VERSION ""

NS_ :

BS_:

BU_: NOONE SENSOR DRIVER MOTOR IO

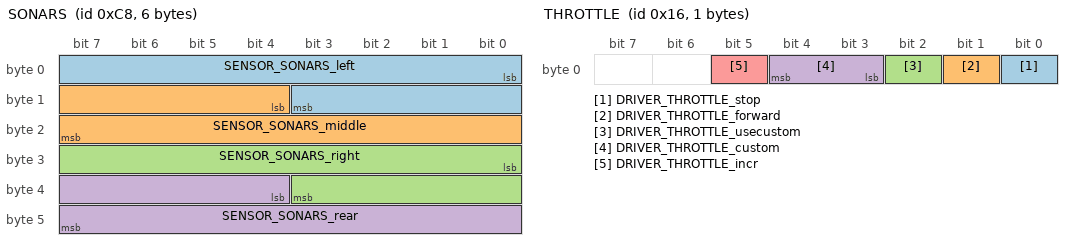
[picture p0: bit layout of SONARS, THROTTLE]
BO_ 200 SONARS: 6 SENSOR
 SG_ SENSOR_SONARS_left : 0|12@1+ (0.1,0) [0|0] "" DRIVER,IO
 SG_ SENSOR_SONARS_middle : 12|12@1+ (0.1,0) [0|0] "" DRIVER,IO
 SG_ SENSOR_SONARS_right : 24|12@1+ (0.1,0) [0|0] "" DRIVER,IO
 SG_ SENSOR_SONARS_rear : 36|12@1+ (0.1,0) [0|0] "" DRIVER,IO

BO_ 20 RESET_MOTOR: 1 DRIVER
 SG_ RESET_MOTOR_cmd : 0|1@1+ (1,0) [0|0] "" MOTOR

BO_ 21 STEER: 1 DRIVER
 SG_ DRIVER_STEER_dir : 0|4@1+ (1,0) [0|4] "" MOTOR

BO_ 22 THROTTLE: 1 DRIVER
 SG_ DRIVER_THROTTLE_stop : 0|1@1+ (1,0) [0|1] "" MOTOR
 SG_ DRIVER_THROTTLE_forward : 1|1@1+ (1,0) [0|1] "" MOTOR
 SG_ DRIVER_THROTTLE_usecustom : 2|1@1+ (1,0) [0|1] "" MOTOR
 SG_ DRIVER_THROTTLE_custom : 3|2@1+ (1,0) [0|3] "" MOTOR
 SG_ DRIVER_THROTTLE_incr : 5|1@1+ (1,0) [0|1] "" MOTOR

BO_ 100 MOTOR_HEARTBEAT: 8 MOTOR
 SG_ MOTOR_HEARTBEAT_cmd : 0|64@1+ (1,0) [0|0] "" DRIVER

BO_ 102 SPEED: 1 MOTOR
 SG_ MOTOR_SPEED_speed : 0|8@1+ (1,0) [0|0] "" DRIVER
 SG_ MOTOR_SPEED_rpm : 8|8@1+ (1,0) [0|0] "" DRIVER

CM_ BU_ NOONE "No node, used to indicate if it's a debug message going to no one";
CM_ BU_ DRIVER "The driver controller driving the car";
CM_ BU_ SENSOR "The sensor controller of the car";
CM_ BU_ MOTOR "The motor controller of the car";
CM_ BO_ 100 "Sync message used to synchronize the controllers";

BA_DEF_  "BusType" STRING ;
BA_DEF_ SG_ "FieldType" STRING ;
BA_DEF_ BO_ "GenMsgCycleTime" INT 0 0;

BA_DEF_DEF_ "BusType" "CAN";
BA_DEF_DEF_ "FieldType" "";

BA_ "GenMsgCycleTime" BO_ 100 1000;
BA_ "GenMsgCycleTime" BO_ 200 100;
BA_ "GenMsgCycleTime" BO_ 300 100;
BA_ "FieldType" SG_ 100 DRIVER_HEARTBEAT_cmd "DRIVER_HEARTBEAT_cmd";

VAL_ 100 DRIVER_HEARTBEAT_cmd 0 "DRIVER_HEARTBEAT_cmd_NOOP" 1 "DRIVER_HEARTBEAT_cmd_SYNC" 2 "DRIVER_HEARTBEAT_cmd_REBOOT";
